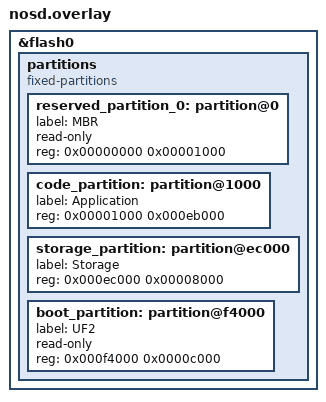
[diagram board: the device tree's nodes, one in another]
/* This board's UF2 bootloader reports SoftDevice: not found. */
&flash0 {
    /delete-node/ partitions;
    partitions {
        compatible = "fixed-partitions";
        #address-cells = <1>;
        #size-cells = <1>;
        reserved_partition_0: partition@0 {
            label = "MBR";
            read-only;
            reg = <0x00000000 0x00001000>;
        };
        code_partition: partition@1000 {
            label = "Application";
            reg = <0x00001000 0x000eb000>;
        };
        storage_partition: partition@ec000 {
            label = "Storage";
            reg = <0x000ec000 0x00008000>;
        };
        boot_partition: partition@f4000 {
            label = "UF2";
            read-only;
            reg = <0x000f4000 0x0000c000>;
        };
    };
};
